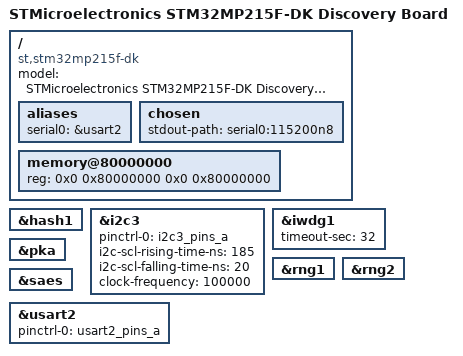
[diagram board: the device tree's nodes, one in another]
// SPDX-License-Identifier: (GPL-2.0-only OR BSD-3-Clause)
/*
 * Copyright (C) STMicroelectronics 2024 - All Rights Reserved
 * Author: Amelie Delaunay <amelie.delaunay@foss.st.com> for STMicroelectronics.
 */

/dts-v1/;

#include "stm32mp215.dtsi"
#include "stm32mp21xf.dtsi"
#include "stm32mp21-lpddr4-1x16Gbits-1x16bits-800MHz.dtsi"
#include "stm32mp21-pinctrl.dtsi"
#include "stm32mp21xxan-pinctrl.dtsi"

/ {
	model = "STMicroelectronics STM32MP215F-DK Discovery Board";
	compatible = "st,stm32mp215f-dk", "st,stm32mp215";

	aliases {
		serial0 = &usart2;
	};

	chosen {
		stdout-path = "serial0:115200n8";
	};

	memory@80000000 {
		device_type = "memory";
		reg = <0x0 0x80000000 0x0 0x80000000>;
	};
};

&hash1 {
	status = "okay";
};

&i2c3 {
	pinctrl-names = "default";
	pinctrl-0 = <&i2c3_pins_a>;
	i2c-scl-rising-time-ns = <185>;
	i2c-scl-falling-time-ns = <20>;
	clock-frequency = <100000>;
	status = "okay";
	#address-cells = <1>;
	#size-cells = <0>;
};

&iwdg1 {
	timeout-sec = <32>;
	status = "okay";
};

&pka {
	status = "okay";
};

&rng1 {
	status = "okay";
};

&rng2 {
	status = "okay";
};

&saes {
	status = "okay";
};

&usart2 {
	pinctrl-names = "default", "idle", "sleep";
	pinctrl-0 = <&usart2_pins_a>;
	status = "okay";
};
